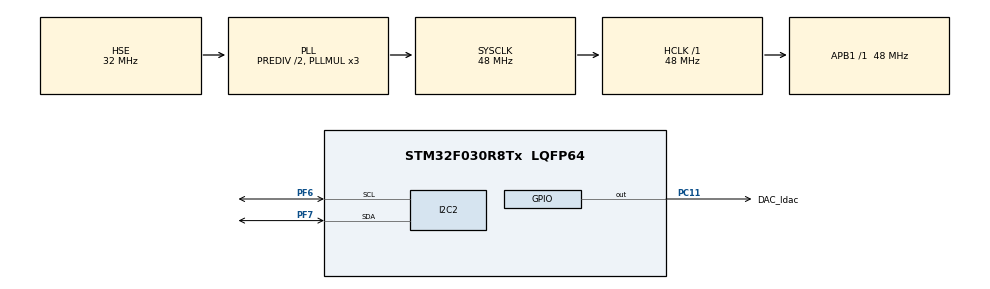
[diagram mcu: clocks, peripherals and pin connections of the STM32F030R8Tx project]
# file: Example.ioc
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I2C2.Timing=0x20303E5D
Mcu.Family=STM32F0
Mcu.Name=STM32F030R8Tx
Mcu.Package=LQFP64
PA13.Mode=Serial_Wire
PA13.Signal=SYS_SWDIO
PA14.Mode=Serial_Wire
PA14.Signal=SYS_SWCLK
PC11.GPIO_Label=DAC_ldac
PC11.PinState=GPIO_PIN_SET
PC11.Signal=GPIO_Output
PF0-OSC_IN.Mode=HSE-External-Oscillator
PF0-OSC_IN.Signal=RCC_OSC_IN
PF1-OSC_OUT.Mode=HSE-External-Oscillator
PF1-OSC_OUT.Signal=RCC_OSC_OUT
PF6.Mode=I2C
PF6.Signal=I2C2_SCL
PF7.Mode=I2C
PF7.Signal=I2C2_SDA
ProjectManager.HeapSize=0x200
ProjectManager.StackSize=0x400
ProjectManager.TargetToolchain=STM32CubeIDE
RCC.AHBFreq_Value=48000000
RCC.APB1Freq_Value=48000000
RCC.APB1TimFreq_Value=48000000
RCC.HCLKFreq_Value=48000000
RCC.HSE_VALUE=32000000
RCC.PLLDivider=RCC_PREDIV_DIV2
RCC.PLLMUL=RCC_PLL_MUL3
RCC.PLLSourceVirtual=RCC_PLLSOURCE_HSE
RCC.SYSCLKFreq_VALUE=48000000
RCC.SYSCLKSource=RCC_SYSCLKSOURCE_PLLCLK
board=custom

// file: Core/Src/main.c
/* USER CODE BEGIN Header */
/**
  ******************************************************************************
  * @file           : main.c
  * @brief          : Main program body
  ******************************************************************************
  * @attention
  *
  * Copyright (c) 2024 STMicroelectronics.
  * All rights reserved.
  *
  * This software is licensed under terms that can be found in the LICENSE file
  * in the root directory of this software component.
  * If no LICENSE file comes with this software, it is provided AS-IS.
  *
  ******************************************************************************
  */
/* USER CODE END Header */
#include "main.h"

/* USER CODE BEGIN Includes */
#include "DAC7578.h"
/* USER CODE END Includes */

I2C_HandleTypeDef hi2c2;

/* USER CODE BEGIN PV */
DAC7578_HandleTypeDef dac;
/* USER CODE END PV */

void SystemClock_Config(void);
static void MX_GPIO_Init(void);
static void MX_I2C2_Init(void);

int main(void)
{

  /* MCU Configuration--------------------------------------------------------*/

  /* Reset of all peripherals, Initializes the Flash interface and the Systick. */
  HAL_Init();

  /* Configure the system clock */
  SystemClock_Config();

  /* Initialize all configured peripherals */
  MX_GPIO_Init();
  MX_I2C2_Init();
  /* USER CODE BEGIN 2 */
    DAC7578_Init(&dac, &hi2c2, 0, DAC_ldac_GPIO_Port, DAC_ldac_Pin);
    DAC7578_write_dac_power_all(&dac, power_on);
  /* USER CODE END 2 */

  /* Infinite loop */
  /* USER CODE BEGIN WHILE */
  while (1)
  {
      for (uint16_t i = 0; i <= 0x0FFF; i++) {
          DAC7578_set_dac_output(&dac, 0, i, false);
          DAC7578_update_dac_output(&dac, 0);
          DAC7578_read_dac_output(&dac, 0, NULL);
      }
    /* USER CODE END WHILE */

  }
}

void SystemClock_Config(void)
{
  RCC_OscInitTypeDef RCC_OscInitStruct = {0};
  RCC_ClkInitTypeDef RCC_ClkInitStruct = {0};

  /** Initializes the RCC Oscillators according to the specified parameters
  * in the RCC_OscInitTypeDef structure.
  */
  RCC_OscInitStruct.OscillatorType = RCC_OSCILLATORTYPE_HSE;
  RCC_OscInitStruct.HSEState = RCC_HSE_ON;
  RCC_OscInitStruct.PLL.PLLState = RCC_PLL_ON;
  RCC_OscInitStruct.PLL.PLLSource = RCC_PLLSOURCE_HSE;
  RCC_OscInitStruct.PLL.PLLMUL = RCC_PLL_MUL3;
  RCC_OscInitStruct.PLL.PREDIV = RCC_PREDIV_DIV2;
  if (HAL_RCC_OscConfig(&RCC_OscInitStruct) != HAL_OK)
  {
    Error_Handler();
  }

  /** Initializes the CPU, AHB and APB buses clocks
  */
  RCC_ClkInitStruct.ClockType = RCC_CLOCKTYPE_HCLK|RCC_CLOCKTYPE_SYSCLK
                              |RCC_CLOCKTYPE_PCLK1;
  RCC_ClkInitStruct.SYSCLKSource = RCC_SYSCLKSOURCE_PLLCLK;
  RCC_ClkInitStruct.AHBCLKDivider = RCC_SYSCLK_DIV1;
  RCC_ClkInitStruct.APB1CLKDivider = RCC_HCLK_DIV1;

  if (HAL_RCC_ClockConfig(&RCC_ClkInitStruct, FLASH_LATENCY_1) != HAL_OK)
  {
    Error_Handler();
  }
}

static void MX_I2C2_Init(void)
{

  hi2c2.Instance = I2C2;
  hi2c2.Init.Timing = 0x20303E5D;
  hi2c2.Init.OwnAddress1 = 0;
  hi2c2.Init.AddressingMode = I2C_ADDRESSINGMODE_7BIT;
  hi2c2.Init.DualAddressMode = I2C_DUALADDRESS_DISABLE;
  hi2c2.Init.OwnAddress2 = 0;
  hi2c2.Init.OwnAddress2Masks = I2C_OA2_NOMASK;
  hi2c2.Init.GeneralCallMode = I2C_GENERALCALL_DISABLE;
  hi2c2.Init.NoStretchMode = I2C_NOSTRETCH_DISABLE;
  if (HAL_I2C_Init(&hi2c2) != HAL_OK)
  {
    Error_Handler();
  }

  /** Configure Analogue filter
  */
  if (HAL_I2CEx_ConfigAnalogFilter(&hi2c2, I2C_ANALOGFILTER_ENABLE) != HAL_OK)
  {
    Error_Handler();
  }

  /** Configure Digital filter
  */
  if (HAL_I2CEx_ConfigDigitalFilter(&hi2c2, 0) != HAL_OK)
  {
    Error_Handler();
  }

}

static void MX_GPIO_Init(void)
{
  GPIO_InitTypeDef GPIO_InitStruct = {0};

  /* GPIO Ports Clock Enable */
  __HAL_RCC_GPIOF_CLK_ENABLE();
  __HAL_RCC_GPIOA_CLK_ENABLE();
  __HAL_RCC_GPIOC_CLK_ENABLE();

  /*Configure GPIO pin Output Level */
  HAL_GPIO_WritePin(DAC_ldac_GPIO_Port, DAC_ldac_Pin, GPIO_PIN_SET);

  /*Configure GPIO pin : DAC_ldac_Pin */
  GPIO_InitStruct.Pin = DAC_ldac_Pin;
  GPIO_InitStruct.Mode = GPIO_MODE_OUTPUT_PP;
  GPIO_InitStruct.Pull = GPIO_NOPULL;
  GPIO_InitStruct.Speed = GPIO_SPEED_FREQ_LOW;
  HAL_GPIO_Init(DAC_ldac_GPIO_Port, &GPIO_InitStruct);

}

void Error_Handler(void)
{
  __disable_irq();
  while (1)
  {
  }
}
